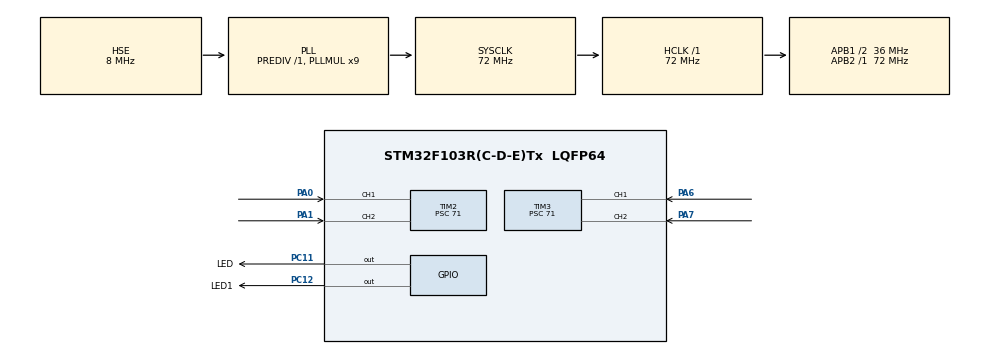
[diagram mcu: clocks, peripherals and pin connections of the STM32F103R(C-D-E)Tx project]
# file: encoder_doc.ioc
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Dma.Request0=TIM2_UP
Dma.Request1=TIM3_CH4/UP
Dma.TIM2_UP.0.Direction=DMA_PERIPH_TO_MEMORY
Dma.TIM2_UP.0.Instance=DMA1_Channel2
Dma.TIM2_UP.0.MemDataAlignment=DMA_MDATAALIGN_HALFWORD
Dma.TIM2_UP.0.MemInc=DMA_MINC_ENABLE
Dma.TIM2_UP.0.Mode=DMA_CIRCULAR
Dma.TIM2_UP.0.PeriphDataAlignment=DMA_PDATAALIGN_HALFWORD
Dma.TIM2_UP.0.PeriphInc=DMA_PINC_DISABLE
Dma.TIM2_UP.0.Priority=DMA_PRIORITY_LOW
Dma.TIM3_CH4/UP.1.Direction=DMA_PERIPH_TO_MEMORY
Dma.TIM3_CH4/UP.1.Instance=DMA1_Channel3
Dma.TIM3_CH4/UP.1.MemDataAlignment=DMA_MDATAALIGN_HALFWORD
Dma.TIM3_CH4/UP.1.MemInc=DMA_MINC_ENABLE
Dma.TIM3_CH4/UP.1.Mode=DMA_CIRCULAR
Dma.TIM3_CH4/UP.1.PeriphDataAlignment=DMA_PDATAALIGN_HALFWORD
Dma.TIM3_CH4/UP.1.PeriphInc=DMA_PINC_DISABLE
Dma.TIM3_CH4/UP.1.Priority=DMA_PRIORITY_LOW
Mcu.Family=STM32F1
Mcu.Name=STM32F103R(C-D-E)Tx
Mcu.Package=LQFP64
NVIC.DMA1_Channel2_IRQn=true\:0\:0\:false\:false\:true\:false
NVIC.DMA1_Channel3_IRQn=true\:0\:0\:false\:false\:true\:false
NVIC.PriorityGroup=NVIC_PRIORITYGROUP_4
NVIC.TIM2_IRQn=true\:0\:0\:false\:false\:true\:true
NVIC.TIM3_IRQn=true\:0\:0\:false\:false\:true\:true
PA0-WKUP.Signal=S_TIM2_CH1_ETR
PA1.Signal=S_TIM2_CH2
PA13.Mode=Serial_Wire
PA13.Signal=SYS_JTMS-SWDIO
PA14.Mode=Serial_Wire
PA14.Signal=SYS_JTCK-SWCLK
PA6.Signal=S_TIM3_CH1
PA7.Signal=S_TIM3_CH2
PC11.GPIO_Label=LED
PC11.Signal=GPIO_Output
PC12.GPIO_Label=LED1
PC12.Signal=GPIO_Output
PD0-OSC_IN.Mode=HSE-External-Oscillator
PD0-OSC_IN.Signal=RCC_OSC_IN
PD1-OSC_OUT.Mode=HSE-External-Oscillator
PD1-OSC_OUT.Signal=RCC_OSC_OUT
ProjectManager.HeapSize=0x200
ProjectManager.StackSize=0x400
ProjectManager.TargetToolchain=MDK-ARM V5
RCC.AHBFreq_Value=72000000
RCC.APB1CLKDivider=RCC_HCLK_DIV2
RCC.APB1Freq_Value=36000000
RCC.APB1TimFreq_Value=72000000
RCC.APB2Freq_Value=72000000
RCC.APB2TimFreq_Value=72000000
RCC.HCLKFreq_Value=72000000
RCC.PLLMUL=RCC_PLL_MUL9
RCC.PLLSourceVirtual=RCC_PLLSOURCE_HSE
RCC.SYSCLKFreq_VALUE=72000000
RCC.SYSCLKSource=RCC_SYSCLKSOURCE_PLLCLK
RCC.USBFreq_Value=72000000
SH.S_TIM2_CH1_ETR.0=TIM2_CH1,Encoder_Interface
SH.S_TIM2_CH2.0=TIM2_CH2,Encoder_Interface
SH.S_TIM3_CH1.0=TIM3_CH1,Encoder_Interface
SH.S_TIM3_CH2.0=TIM3_CH2,Encoder_Interface
TIM2.EncoderMode=TIM_ENCODERMODE_TI12
TIM2.Period=0xffff-1
TIM2.Prescaler=71
TIM3.Period=0xffff-1
TIM3.Prescaler=71
board=encoder_doc

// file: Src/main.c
/**
  ******************************************************************************
  * File Name          : main.c
  * Description        : Main program body
  ******************************************************************************
  ** This notice applies to any and all portions of this file
  * that are not between comment pairs USER CODE BEGIN and
  * USER CODE END. Other portions of this file, whether
  * inserted by the user or by software development tools
  * are owned by their respective copyright owners.
  *
  * COPYRIGHT(c) 2020 STMicroelectronics
  *
  * Redistribution and use in source and binary forms, with or without modification,
  * are permitted provided that the following conditions are met:
  *   1. Redistributions of source code must retain the above copyright notice,
  *      this list of conditions and the following disclaimer.
  *   2. Redistributions in binary form must reproduce the above copyright notice,
  *      this list of conditions and the following disclaimer in the documentation
  *      and/or other materials provided with the distribution.
  *   3. Neither the name of STMicroelectronics nor the names of its contributors
  *      may be used to endorse or promote products derived from this software
  *      without specific prior written permission.
  *
  * THIS SOFTWARE IS PROVIDED BY THE COPYRIGHT HOLDERS AND CONTRIBUTORS "AS IS"
  * AND ANY EXPRESS OR IMPLIED WARRANTIES, INCLUDING, BUT NOT LIMITED TO, THE
  * IMPLIED WARRANTIES OF MERCHANTABILITY AND FITNESS FOR A PARTICULAR PURPOSE ARE
  * DISCLAIMED. IN NO EVENT SHALL THE COPYRIGHT HOLDER OR CONTRIBUTORS BE LIABLE
  * FOR ANY DIRECT, INDIRECT, INCIDENTAL, SPECIAL, EXEMPLARY, OR CONSEQUENTIAL
  * DAMAGES (INCLUDING, BUT NOT LIMITED TO, PROCUREMENT OF SUBSTITUTE GOODS OR
  * SERVICES; LOSS OF USE, DATA, OR PROFITS; OR BUSINESS INTERRUPTION) HOWEVER
  * CAUSED AND ON ANY THEORY OF LIABILITY, WHETHER IN CONTRACT, STRICT LIABILITY,
  * OR TORT (INCLUDING NEGLIGENCE OR OTHERWISE) ARISING IN ANY WAY OUT OF THE USE
  * OF THIS SOFTWARE, EVEN IF ADVISED OF THE POSSIBILITY OF SUCH DAMAGE.
  *
  ******************************************************************************
  */

#include "main.h"
#include "stm32f1xx_hal.h"

TIM_HandleTypeDef htim2;
TIM_HandleTypeDef htim3;
DMA_HandleTypeDef hdma_tim2_up;
DMA_HandleTypeDef hdma_tim3_ch4_up;

/* USER CODE BEGIN PV */
/* Private variables ---------------------------------------------------------*/
volatile uint32_t count_1 = 0, count_2 = 0;
/* USER CODE END PV */

void SystemClock_Config(void);
static void MX_GPIO_Init(void);
static void MX_DMA_Init(void);
static void MX_TIM2_Init(void);
static void MX_TIM3_Init(void);

/* USER CODE BEGIN PFP */
/* Private function prototypes -----------------------------------------------*/

/* USER CODE END PFP */

/* USER CODE BEGIN 0 */
void Endcoder(void) {
	HAL_TIM_Encoder_Start(&htim2, TIM_CHANNEL_1 | TIM_CHANNEL_2);
	HAL_TIM_Encoder_Start(&htim3, TIM_CHANNEL_1 | TIM_CHANNEL_2);
	count_1 = __HAL_TIM_GET_COUNTER(&htim2) ;
	count_2 = __HAL_TIM_GET_COUNTER(&htim3) ;
	HAL_Delay(5);
	HAL_TIM_Encoder_Stop(&htim2, TIM_CHANNEL_1 | TIM_CHANNEL_2);
	HAL_TIM_Encoder_Stop(&htim3, TIM_CHANNEL_1 | TIM_CHANNEL_2);
}
/* USER CODE END 0 */

int main(void)
{

  /* MCU Configuration----------------------------------------------------------*/

  /* Reset of all peripherals, Initializes the Flash interface and the Systick. */
  HAL_Init();

  /* Configure the system clock */
  SystemClock_Config();

  /* Initialize all configured peripherals */
  MX_GPIO_Init();
  MX_DMA_Init();
  MX_TIM2_Init();
  MX_TIM3_Init();

  /* USER CODE BEGIN 2 */
//HAL_TIM_Encoder_Start(&htim2, TIM_CHANNEL_1 | TIM_CHANNEL_2);
//HAL_TIM_Encoder_Start(&htim3, TIM_CHANNEL_1 | TIM_CHANNEL_2);
  /* USER CODE END 2 */

  /* Infinite loop */
  while (1)
  {
		HAL_GPIO_TogglePin(LED1_GPIO_Port,LED1_Pin);
		HAL_Delay(100);
		HAL_GPIO_TogglePin(LED_GPIO_Port,LED_Pin);
		HAL_Delay(100);
count_1 = __HAL_TIM_GET_COUNTER(&htim2);
count_2 = __HAL_TIM_GET_COUNTER(&htim3);
		//Endcoder();
  }

}

/** System Clock Configuration
*/
void SystemClock_Config(void)
{

  RCC_OscInitTypeDef RCC_OscInitStruct;
  RCC_ClkInitTypeDef RCC_ClkInitStruct;

    /**Initializes the CPU, AHB and APB busses clocks
    */
  RCC_OscInitStruct.OscillatorType = RCC_OSCILLATORTYPE_HSE;
  RCC_OscInitStruct.HSEState = RCC_HSE_ON;
  RCC_OscInitStruct.HSEPredivValue = RCC_HSE_PREDIV_DIV1;
  RCC_OscInitStruct.HSIState = RCC_HSI_ON;
  RCC_OscInitStruct.PLL.PLLState = RCC_PLL_ON;
  RCC_OscInitStruct.PLL.PLLSource = RCC_PLLSOURCE_HSE;
  RCC_OscInitStruct.PLL.PLLMUL = RCC_PLL_MUL9;
  if (HAL_RCC_OscConfig(&RCC_OscInitStruct) != HAL_OK)
  {
    _Error_Handler(__FILE__, __LINE__);
  }

    /**Initializes the CPU, AHB and APB busses clocks
    */
  RCC_ClkInitStruct.ClockType = RCC_CLOCKTYPE_HCLK|RCC_CLOCKTYPE_SYSCLK
                              |RCC_CLOCKTYPE_PCLK1|RCC_CLOCKTYPE_PCLK2;
  RCC_ClkInitStruct.SYSCLKSource = RCC_SYSCLKSOURCE_PLLCLK;
  RCC_ClkInitStruct.AHBCLKDivider = RCC_SYSCLK_DIV1;
  RCC_ClkInitStruct.APB1CLKDivider = RCC_HCLK_DIV2;
  RCC_ClkInitStruct.APB2CLKDivider = RCC_HCLK_DIV1;

  if (HAL_RCC_ClockConfig(&RCC_ClkInitStruct, FLASH_LATENCY_2) != HAL_OK)
  {
    _Error_Handler(__FILE__, __LINE__);
  }

    /**Configure the Systick interrupt time
    */
  HAL_SYSTICK_Config(HAL_RCC_GetHCLKFreq()/1000);

    /**Configure the Systick
    */
  HAL_SYSTICK_CLKSourceConfig(SYSTICK_CLKSOURCE_HCLK);

  /* SysTick_IRQn interrupt configuration */
  HAL_NVIC_SetPriority(SysTick_IRQn, 0, 0);
}

/* TIM2 init function */
static void MX_TIM2_Init(void)
{

  TIM_Encoder_InitTypeDef sConfig;
  TIM_MasterConfigTypeDef sMasterConfig;

  htim2.Instance = TIM2;
  htim2.Init.Prescaler = 71;
  htim2.Init.CounterMode = TIM_COUNTERMODE_UP;
  htim2.Init.Period = 9999;
  htim2.Init.ClockDivision = TIM_CLOCKDIVISION_DIV1;
  htim2.Init.AutoReloadPreload = TIM_AUTORELOAD_PRELOAD_DISABLE;
  sConfig.EncoderMode = TIM_ENCODERMODE_TI12;
  sConfig.IC1Polarity = TIM_ICPOLARITY_RISING;
  sConfig.IC1Selection = TIM_ICSELECTION_DIRECTTI;
  sConfig.IC1Prescaler = TIM_ICPSC_DIV1;
  sConfig.IC1Filter = 0;
  sConfig.IC2Polarity = TIM_ICPOLARITY_RISING;
  sConfig.IC2Selection = TIM_ICSELECTION_DIRECTTI;
  sConfig.IC2Prescaler = TIM_ICPSC_DIV1;
  sConfig.IC2Filter = 0;
  if (HAL_TIM_Encoder_Init(&htim2, &sConfig) != HAL_OK)
  {
    _Error_Handler(__FILE__, __LINE__);
  }

  sMasterConfig.MasterOutputTrigger = TIM_TRGO_RESET;
  sMasterConfig.MasterSlaveMode = TIM_MASTERSLAVEMODE_DISABLE;
  if (HAL_TIMEx_MasterConfigSynchronization(&htim2, &sMasterConfig) != HAL_OK)
  {
    _Error_Handler(__FILE__, __LINE__);
  }

}

/* TIM3 init function */
static void MX_TIM3_Init(void)
{

  TIM_Encoder_InitTypeDef sConfig;
  TIM_MasterConfigTypeDef sMasterConfig;

  htim3.Instance = TIM3;
  htim3.Init.Prescaler = 71;
  htim3.Init.CounterMode = TIM_COUNTERMODE_UP;
  htim3.Init.Period = 9999;
  htim3.Init.ClockDivision = TIM_CLOCKDIVISION_DIV1;
  htim3.Init.AutoReloadPreload = TIM_AUTORELOAD_PRELOAD_DISABLE;
  sConfig.EncoderMode = TIM_ENCODERMODE_TI12;
  sConfig.IC1Polarity = TIM_ICPOLARITY_RISING;
  sConfig.IC1Selection = TIM_ICSELECTION_DIRECTTI;
  sConfig.IC1Prescaler = TIM_ICPSC_DIV1;
  sConfig.IC1Filter = 0;
  sConfig.IC2Polarity = TIM_ICPOLARITY_RISING;
  sConfig.IC2Selection = TIM_ICSELECTION_DIRECTTI;
  sConfig.IC2Prescaler = TIM_ICPSC_DIV1;
  sConfig.IC2Filter = 0;
  if (HAL_TIM_Encoder_Init(&htim3, &sConfig) != HAL_OK)
  {
    _Error_Handler(__FILE__, __LINE__);
  }

  sMasterConfig.MasterOutputTrigger = TIM_TRGO_RESET;
  sMasterConfig.MasterSlaveMode = TIM_MASTERSLAVEMODE_DISABLE;
  if (HAL_TIMEx_MasterConfigSynchronization(&htim3, &sMasterConfig) != HAL_OK)
  {
    _Error_Handler(__FILE__, __LINE__);
  }

}

static void MX_DMA_Init(void)
{
  /* DMA controller clock enable */
  __HAL_RCC_DMA1_CLK_ENABLE();

  /* DMA interrupt init */
  /* DMA1_Channel2_IRQn interrupt configuration */
  HAL_NVIC_SetPriority(DMA1_Channel2_IRQn, 0, 0);
  HAL_NVIC_EnableIRQ(DMA1_Channel2_IRQn);
  /* DMA1_Channel3_IRQn interrupt configuration */
  HAL_NVIC_SetPriority(DMA1_Channel3_IRQn, 0, 0);
  HAL_NVIC_EnableIRQ(DMA1_Channel3_IRQn);

}

/** Configure pins as
        * Analog
        * Input
        * Output
        * EVENT_OUT
        * EXTI
*/
static void MX_GPIO_Init(void)
{

  GPIO_InitTypeDef GPIO_InitStruct;

  /* GPIO Ports Clock Enable */
  __HAL_RCC_GPIOD_CLK_ENABLE();
  __HAL_RCC_GPIOA_CLK_ENABLE();
  __HAL_RCC_GPIOC_CLK_ENABLE();

  /*Configure GPIO pin Output Level */
  HAL_GPIO_WritePin(GPIOC, LED_Pin|LED1_Pin, GPIO_PIN_RESET);

  /*Configure GPIO pins : LED_Pin LED1_Pin */
  GPIO_InitStruct.Pin = LED_Pin|LED1_Pin;
  GPIO_InitStruct.Mode = GPIO_MODE_OUTPUT_PP;
  GPIO_InitStruct.Speed = GPIO_SPEED_FREQ_LOW;
  HAL_GPIO_Init(GPIOC, &GPIO_InitStruct);

}

void _Error_Handler(char * file, int line)
{
  while(1)
  {
  }
}

/************************ (C) COPYRIGHT STMicroelectronics *****END OF FILE****/
